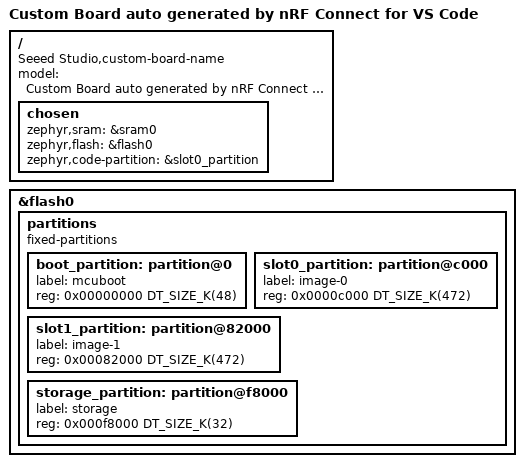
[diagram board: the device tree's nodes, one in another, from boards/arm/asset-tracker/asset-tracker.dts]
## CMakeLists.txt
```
cmake_minimum_required(VERSION 3.20.0)

find_package(Zephyr REQUIRED HINTS $ENV{ZEPHYR_BASE})
project(wm1110-asset-tracker)

FILE(GLOB app_sources
    src/*.c
    src/uplink/*.c
    src/peripherals/*.c
)

target_sources(app PRIVATE ${app_sources})

zephyr_include_directories(
    include
)
```

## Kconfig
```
mainmenu "AWS IoT Sidewalk Asset Tracker"

menu "Asset Tracker"

config TRACKER_LOG
	bool
	default TRACKER
	imply LOG

config LONG_PRESS_PER_MS
        prompt "Long button press time (ms)"
        int
        default 10000
        help
               Period of time in ms for a button press to be considered a long press.

config IN_MOTION_PER_M
        prompt "In motion period (m)"
        int
        default 15
        help
               Time in seconds device will stay in the motion state from last motion event.

config MOTION_SCAN_PER_S
        prompt "Motion uplink period (s)"
        int
        default 240
        help
               Delay in seconds between scanning and uplinking when the device is in motion.

config STATIC_SCAN_PER_M
        prompt "Static uplink period (m)"
        int
        default 1
        help
               Delay in minutes between scanning and uplinking when the device is static.

config ASSET_TRACKER_CLI
        prompt "Enable the Asset Tracker serial shell CLI"
        bool
        default y
        help
               Enables(y) or disables(n) the zephyr shell for the Asset Tracker.

endmenu

module = TRACKER
module-str = IMP
source "${ZEPHYR_BASE}/subsys/logging/Kconfig.template.log_config"

rsource "${ZEPHYR_BASE}/../sidewalk/samples/common/Kconfig.defconfig"

source "Kconfig.zephyr"
```

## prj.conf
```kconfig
CONFIG_ASSET_TRACKER_CLI=y
CONFIG_TRACKER_LOG_LEVEL_INF=y

CONFIG_NVS_LOG_LEVEL_WRN=y

CONFIG_ADC_SHELL=n
CONFIG_DEVICE_SHELL=n
CONFIG_DEVMEM_SHELL=n
CONFIG_FLASH_SHELL=n
CONFIG_HWINFO_SHELL=n
CONFIG_I2C_SHELL=n
CONFIG_CLOCK_CONTROL_NRF_SHELL=n
CONFIG_REGULATOR_SHELL=n
CONFIG_SENSOR_SHELL=n

CONFIG_NEWLIB_LIBC_FLOAT_SCANF=n

CONFIG_GPIO=y
CONFIG_LED=y
CONFIG_SENSOR=y
CONFIG_ADC=y
CONFIG_I2C=y
CONFIG_SPI=y
CONFIG_REGULATOR=y
CONFIG_PM_DEVICE=y
CONFIG_SHT4X=y
CONFIG_LIS2DH=y

CONFIG_PINCTRL=y
CONFIG_GPIO_AS_PINRESET=y

CONFIG_STDOUT_CONSOLE=y
CONFIG_UART_CONSOLE=y
CONFIG_UART_LINE_CTRL=y
CONFIG_CONSOLE=y
CONFIG_SERIAL=y
CONFIG_LOG=y

CONFIG_RESET_ON_FATAL_ERROR=y
CONFIG_NEWLIB_LIBC=y
CONFIG_NEWLIB_LIBC_FLOAT_PRINTF=y
CONFIG_CBPRINTF_FP_SUPPORT=y
CONFIG_LOG_PRINTK=y
CONFIG_LOG_MODE_IMMEDIATE=y

CONFIG_USB_DEVICE_STACK=y
CONFIG_USB_CDC_ACM_LOG_LEVEL_OFF=y
CONFIG_USB_DEVICE_MANUFACTURER="Seeed Technology"
CONFIG_USB_DEVICE_PRODUCT="Asset Tracker"
CONFIG_USB_DEVICE_VID=0x2886
CONFIG_USB_DEVICE_PID=0x0052

CONFIG_SHELL=y
CONFIG_SHELL_PROMPT_UART="asset-tracker > "

CONFIG_BT_DEVICE_NAME="Tracker"

CONFIG_RESET_ON_FATAL_ERROR=y
CONFIG_USE_DT_CODE_PARTITION=y
CONFIG_BUILD_OUTPUT_UF2=y
CONFIG_KERNEL_BIN_NAME="IMP"

CONFIG_PARTITION_MANAGER_ENABLED=n
```

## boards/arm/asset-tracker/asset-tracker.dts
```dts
/dts-v1/;
#include <nordic/nrf52840_qfaa.dtsi>
#include "asset-tracker-pinctrl.dtsi"

/ {
	model = "Custom Board auto generated by nRF Connect for VS Code";
	compatible = "Seeed Studio,custom-board-name";

	chosen {
		zephyr,sram = &sram0;
		zephyr,flash = &flash0;
		zephyr,code-partition = &slot0_partition;
	};
};

&flash0 {
	partitions {
		compatible = "fixed-partitions";
		#address-cells = <1>;
		#size-cells = <1>;

		boot_partition: partition@0 {
			label = "mcuboot";
			reg = <0x00000000 DT_SIZE_K(48)>;
		};

		slot0_partition: partition@c000 {
			label = "image-0";
			reg = <0x0000c000 DT_SIZE_K(472)>;
		};

		slot1_partition: partition@82000 {
			label = "image-1";
			reg = <0x00082000 DT_SIZE_K(472)>;
		};

		storage_partition: partition@f8000 {
			label = "storage";
			reg = <0x000f8000 DT_SIZE_K(32)>;
		};
	};
};
```

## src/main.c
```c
#include <stdint.h>
#include <stdbool.h>
#include "asset_tracker.h"

#include <zephyr/kernel.h>

#include "peripherals/at_led.h"
#include "peripherals/at_button.h"
#include "peripherals/at_sht41.h"
#include "peripherals/at_lis3dh.h"
#include "peripherals/at_usb.h"

#include <zephyr/logging/log.h>
LOG_MODULE_REGISTER(main, CONFIG_TRACKER_LOG_LEVEL);

/* 1000 msec = 1 sec */
#define LED_FAST   100
#define LED_WS	   2000
#define LED_SLOW   1000

int main(void)
{
	init_at_usb();
	#if defined(CONFIG_LOG)
	k_msleep(2000);
	#endif

	init_at_led();
	init_at_button();
	init_at_sht41();
	init_at_lis3dh();

	LOG_INF("Starting Device...");

	if (at_thread_init()) {
		LOG_ERR("Failed to start at thread");
	}

	while (1) {
		if(button_long_press == true) { 
			at_led_toggle();
			k_msleep(LED_FAST);
		} else {
			at_led_toggle();
			k_msleep(LED_SLOW);
		}
	}
	return 0;
}
```

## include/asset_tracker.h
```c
#ifndef ASSET_TRACKER_H
#define ASSET_TRACKER_H

#define RECEIVE_TASK_STACK_SIZE (4096)
#define RECEIVE_TASK_PRIORITY (CONFIG_SIDEWALK_THREAD_PRIORITY + 1)

#define LINK_DOWN 0
#define LINK_UP 1

typedef enum uplink_msg_types {
	SERIAL_PUSH_T,
	NOLOC_T,
	WIFI_T,
	GNSS_T,
	UNSET_T,
} uplink_msg_t;

struct at_sensors {
	double temp;
	double hum;
	double max_accel_x;
	double max_accel_y;
	double max_accel_z;
	double peak_accel;
};

enum at_sidewalk_state {
	STATE_SIDEWALK_INIT,
	STATE_SIDEWALK_READY,
	STATE_SIDEWALK_NOT_READY,
	STATE_SIDEWALK_SECURE_CONNECTION,
};

enum at_state {
	AT_STATE_INIT,
	AT_STATE_RUN
};

struct at_config{
    uint16_t max_rec;
    uint8_t motion_period;
    uint8_t scan_freq_motion;
    uint8_t motion_thres;
    uint8_t scan_freq_static;
};

typedef struct at_context {
	enum at_state state;
	uplink_msg_t uplink_type;
	bool connection_request;
	bool motion;
	struct at_sensors sensors;
    struct at_config at_conf;
} at_ctx_t;

typedef enum at_events {
	EVENT_NONE,
	BUTTON_EVENT_SHORT,
	BUTTON_EVENT_LONG,
    MOTION_EVENT,
	EVENT_SEND_UPLINK,
    EVENT_SCAN_SENSORS,
	EVENT_UPLINK_COMPLETE,
} at_event_t;


void at_event_send(at_event_t event);

int at_thread_init(void);

#endif /* ASSET_TRACKER_H */
```

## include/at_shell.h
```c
#ifndef AT_SHELL_H
#define AT_SHELL_H

#include <asset_tracker.h>

#define CMD_RETURN_OK 0
#define CMD_RETURN_HELP 1
#define CMD_RETURN_ARGUMENT_INVALID -EINVAL
#define CMD_RETURN_NOT_EXECUTED -ENOEXEC

typedef enum { Val, Err } result_t;

#define Result(value_t, error_e)                                                                   \
	struct {                                                                                   \
		result_t result;                                                                   \
		union {                                                                            \
			value_t val;                                                               \
			error_e err;                                                               \
		} val_or_err;                                                                      \
	}

#define Result_Val(value)                                                                          \
	{                                                                                          \
		.result = Val, .val_or_err.val = value                                             \
	}
#define Result_Err(error_code)                                                                     \
	{                                                                                          \
		.result = Err, .val_or_err.err = error_code                                        \
	}

#define DECLARE_RESULT(value_t, name, error_cases...)                                              \
	enum name##_error_cases{ error_cases };                                                    \
	typedef Result(value_t, enum name##_error_cases) name;


void send_scan_result(at_ctx_t *at_context);

void AT_CLI_init(at_ctx_t *at_context);
#endif /* AT_SHELL_H */
```

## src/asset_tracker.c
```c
#include <zephyr/kernel.h>
#include <zephyr/kernel/thread_stack.h>

#if defined(CONFIG_ASSET_TRACKER_CLI)
#include "at_shell.h"
#endif

#include <zephyr/logging/log.h>
LOG_MODULE_REGISTER(asset_tracker, CONFIG_TRACKER_LOG_LEVEL);

#include <asset_tracker.h>
#include "peripherals/at_lis3dh.h"
#include "peripherals/at_sht41.h"
#include "peripherals/at_timers.h"
#include "uplink/at_uplink.h"

static struct k_thread at_thread;
K_THREAD_STACK_DEFINE(at_thread_stack, 8192);
K_MSGQ_DEFINE(at_thread_msgq, sizeof(at_event_t), 10, 4);

static at_ctx_t asset_tracker_context = {0};

static void at_app_entry(void *ctx, void *unused, void *unused2)
{
	at_ctx_t *at_ctx = (at_ctx_t *)ctx;
	ARG_UNUSED(unused);
	ARG_UNUSED(unused2);
	LOG_DBG("Starting %s ...", __FUNCTION__);

	while (true) {
		at_event_t event = EVENT_NONE;

		if (!k_msgq_get(&at_thread_msgq, &event, K_FOREVER)) {
			switch (event) {				
				case BUTTON_EVENT_SHORT:
					LOG_INF("Immediate scan and uplink triggered...");
					scan_timer_set_and_run(K_MSEC(100));
					break;
				
				case BUTTON_EVENT_LONG:
					LOG_INF("Long press...");
					break;

				case EVENT_SEND_UPLINK:
					LOG_INF("Sending uplink...");
					at_ctx->uplink_type = SERIAL_PUSH_T;
					at_send_uplink(at_ctx);
					break;

				case EVENT_SCAN_SENSORS:
					LOG_INF("Scanning sensors...");
					get_temp_hum(&at_ctx->sensors);
					get_accel(&at_ctx->sensors);
					break;
				default:
					LOG_ERR("Invalid Event received!, %d", event);
			}
		}
	}
}

void at_event_send(at_event_t event)
{
	int ret = k_msgq_put(&at_thread_msgq, (void *)&event,
			     k_is_in_isr() ? K_NO_WAIT : K_FOREVER);

	if (ret) {
		LOG_ERR("Failed to send event to asset tracker thread. err: %d", ret);
	}
}

int at_thread_init(void)
{
	asset_tracker_context.at_conf = (struct at_config) {
		.max_rec = 100,
		.motion_period = CONFIG_IN_MOTION_PER_M,
		.scan_freq_motion = CONFIG_MOTION_SCAN_PER_S,
		.motion_thres = 5,
		.scan_freq_static = CONFIG_STATIC_SCAN_PER_M,
	};

	#if defined(CONFIG_ASSET_TRACKER_CLI)
	AT_CLI_init(&asset_tracker_context);
	#endif

	(void)k_thread_create(&at_thread, at_thread_stack,
			      K_THREAD_STACK_SIZEOF(at_thread_stack), at_app_entry,
			      &asset_tracker_context, NULL, NULL, 14, 0, K_NO_WAIT);

	return 0;
}
```

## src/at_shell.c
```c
#include <stdio.h>
#include <stdlib.h>
#include <string.h>
#include <sys/types.h>

#include <zephyr/kernel.h>
#include <zephyr/shell/shell.h>
#include "at_shell.h"

#include <zephyr/logging/log.h>
LOG_MODULE_REGISTER(at_shell, CONFIG_TRACKER_LOG_LEVEL);

#define AT_STACK_SIZE 5120
#define AT_WORKER_PRIO 5

struct k_work_q at_work_q;
K_THREAD_STACK_DEFINE(at_work_q_stack, AT_STACK_SIZE);

static at_ctx_t *atcontext;

DECLARE_RESULT(size_t, StrToHexRet, MAC_INVALID);
DECLARE_RESULT(uint8_t, HexToByteRet, NOT_HEX);
DECLARE_RESULT(uint8_t, StrToDecRet, OUT_RANGE);

void AT_CLI_init(at_ctx_t *at_context)
{
	atcontext = at_context;

	k_work_queue_init(&at_work_q);

	k_work_queue_start(&at_work_q, at_work_q_stack,
			   K_THREAD_STACK_SIZEOF(at_work_q_stack), AT_WORKER_PRIO, NULL);
}
```
